# PIC32CX5112MTSH128S1 register map
Vendor: Microchip Technology; Series: PIC32CXMTSH; File version: 0
CPU: CM4 r0p1, little endian, MPU, FPU, 4 interrupt priority bits, 96 interrupts
Registers are 32-bit, read-write, reset 0x0 unless marked. A register's access mark holds for its fields unless they carry their own. Offsets are from the block's base; [hi:lo] are bit positions; {n}, {i} and the like mark numbered series.

## FPB — Flash Patch and Breakpoint
Base 0xE0002000
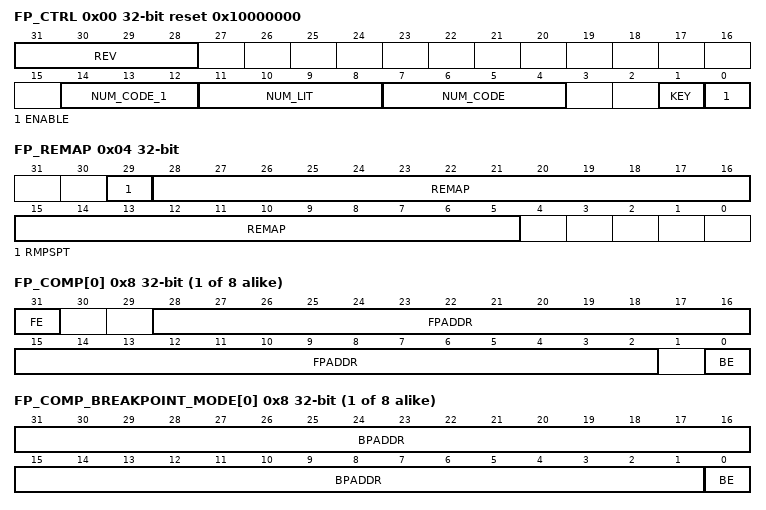
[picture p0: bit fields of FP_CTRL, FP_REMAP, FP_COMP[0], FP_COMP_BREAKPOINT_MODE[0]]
0x00 FP_CTRL reset 0x10000000 — Flash Patch Control Register
  [31:28] REV — Revision
  [14:12] NUM_CODE_1 — Number of implemented code comparators bits [6:4]
  [11:8] NUM_LIT — Number of literal comparators
  [7:4] NUM_CODE — Number of implemented code comparators bits [3:0]
  [1] KEY — FP_CTRL write-enable key
  [0] ENABLE — Flash Patch global enable
0x04 FP_REMAP — Flash Patch Remap Register
  [29] RMPSPT — Remap supported
  [28:5] REMAP — Remap address
{0x8+4i} FP_COMP[{i}] (i=0..7) — Flash Patch Comparator Register n
  [31] FE — Flash Patch enable
  [28:2] FPADDR — Flash Patch address
  [0] BE — Breakpoint enable
{0x8+4i} FP_COMP_BREAKPOINT_MODE[{i}] (i=0..7) (alternate view of FP_COMP[{i}]) — Flash Patch Comparator Register n
  [31:1] BPADDR — Breakpoint address
  [0] BE — Breakpoint enable
0xFB0 LAR wo — FPB Software Lock Access Register
  [31:0] KEY — Lock access control
    0xC5ACCE55=UNLOCK (Unlock key value)
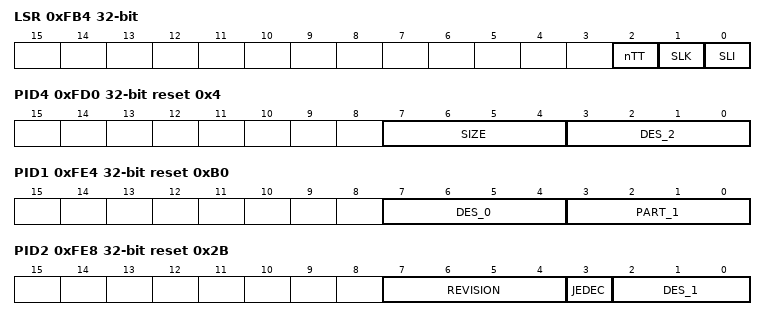
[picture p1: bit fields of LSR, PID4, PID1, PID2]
0xFB4 LSR ro — FPB Software Lock Status Register
  [2] nTT — Not thirty-two bit
  [1] SLK — Software Lock status
  [0] SLI — Software Lock implemented
0xFD0 PID4 ro reset 0x4 — FP Peripheral Identification Register 4
  [7:4] SIZE — 4KB count
  [3:0] DES_2 — JEP106 continuation code
{0xFC0+4i} PID{i} ro (i=5..7) — FP Peripheral Identification Register {i}
0xFE0 PID0 ro reset 0x3 — FP Peripheral Identification Register 0
  [7:0] PART_0 — Part number bits[7:0]
0xFE4 PID1 ro reset 0xB0 — FP Peripheral Identification Register 1
  [7:4] DES_0 — JEP106 identification code bits [3:0]
  [3:0] PART_1 — Part number bits[11:8]
0xFE8 PID2 ro reset 0x2B — FP Peripheral Identification Register 2
  [7:4] REVISION — Component revision
  [3] JEDEC — JEDEC assignee value is used
  [2:0] DES_1 — JEP106 identification code bits[6:4]
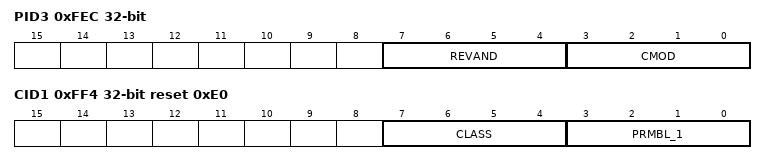
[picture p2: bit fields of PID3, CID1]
0xFEC PID3 ro — FP Peripheral Identification Register 3
  [7:4] REVAND
  [3:0] CMOD — Customer Modified
0xFF0 CID0 ro reset 0xD — FP Component Identification Register 0
  [7:0] PRMBL_0 — CoreSight component identification preamble
0xFF4 CID1 ro reset 0xE0 — FP Component Identification Register 1
  [7:4] CLASS — CoreSight component class
  [3:0] PRMBL_1 — CoreSight component identification preamble
0xFF8 CID2 ro reset 0x5 — FP Component Identification Register 2
  [7:0] PRMBL_2 — CoreSight component identification preamble
0xFFC CID3 ro reset 0xB1 — FP Component Identification Register 3
  [7:0] PRMBL_3 — CoreSight component identification preamble

## FPU — Floating Point Unit
Base 0xE000EF30
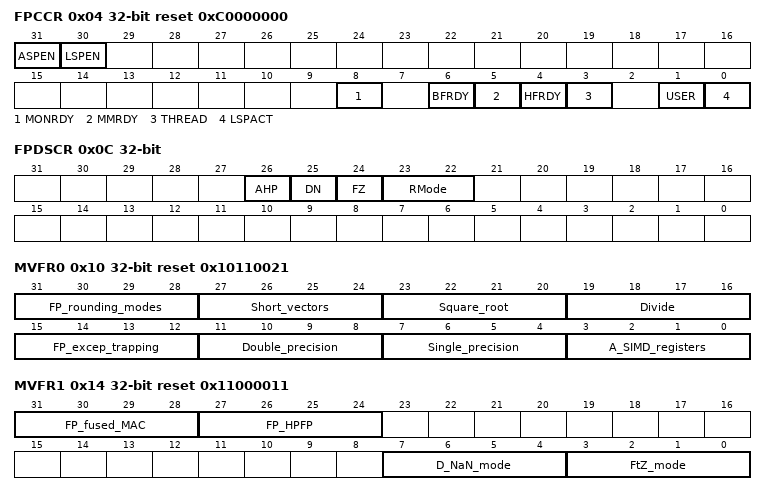
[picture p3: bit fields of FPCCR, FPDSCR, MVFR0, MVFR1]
0x04 FPCCR reset 0xC0000000 — Floating-point Context Control Register
  [31] ASPEN — Enables CONTROL.FPCA setting on execution of a floating-point instruction. This results in automatic hardware state preservation and restoration, for floating-point context, on exception entry and exit.
  [30] LSPEN — Enable automatic lazy state preservation for floating-point context.
  [8] MONRDY — DebugMonitor is enabled and priority permits setting MON_PEND when the floating-point stack frame was allocated.
  [6] BFRDY — BusFault is enabled and priority permitted setting the BusFault handler to the pending state when the floating-point stack frame was allocated.
  [5] MMRDY — MemManage is enabled and priority permitted setting the MemManage handler to the pending state when the floating-point stack frame was allocated.
  [4] HFRDY — Priority permitted setting the HardFault handler to the pending state when the floating-point stack frame was allocated.
  [3] THREAD — Mode was Thread Mode when the floating-point stack frame was allocated.
  [1] USER — Privilege level was user when the floating-point stack frame was allocated.
  [0] LSPACT — Lazy state preservation is active. Floating-point stack frame has been allocated but saving state to it has been deferred.
0x08 FPCAR — Floating-point Context Address Register
  [31:3] ADDRESS — The location of the unpopulated floating-point register space allocated on an exception stack frame.
0x0C FPDSCR — Floating-point Default Status Control Register
  [26] AHP — Default value for FPSCR.AHP.
  [25] DN — Default value for FPSCR.DN.
  [24] FZ — Default value for FPSCR.FZ.
  [23:22] RMode — Default value for FPSCR.RMode.
0x10 MVFR0 ro reset 0x10110021 — Media and VFP Feature Register 0
  [31:28] FP_rounding_modes — Indicates the rounding modes supported by the FP floating-point hardware
  [27:24] Short_vectors — Indicates the hardware support for FP short vectors
  [23:20] Square_root — Indicates the hardware support for FP square root operations
  [19:16] Divide — Indicates the hardware support for FP divide operations
  [15:12] FP_excep_trapping — Indicates whether the FP hardware implementation supports exception trapping
  [11:8] Double_precision — Indicates the hardware support for FP double-precision operations
  [7:4] Single_precision — Indicates the hardware support for FP single-precision operations
  [3:0] A_SIMD_registers — Indicates the size of the FP register bank
0x14 MVFR1 ro reset 0x11000011 — Media and VFP Feature Register 1
  [31:28] FP_fused_MAC — Indicates whether the FP supports fused multiply accumulate operations
  [27:24] FP_HPFP — Floating Point Half-Precision and double-precision
  [7:4] D_NaN_mode — Indicates whether the FP hardware implementation supports only the Default NaN mode
  [3:0] FtZ_mode — Indicates whether the FP hardware implementation supports only the Flush-to-Zero mode of operation
0x18 MVFR2 ro reset 0x40 — Media and VFP Feature Register 2
  [7:4] VFP_Misc — Indicates the hardware support for FP miscellaneous features
